VERSION ""

NS_ :

BS_:
BU_: aem_lambda
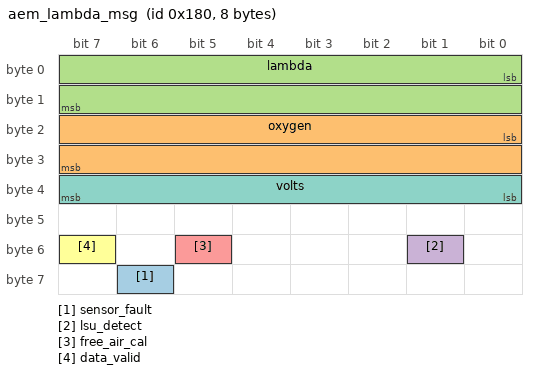
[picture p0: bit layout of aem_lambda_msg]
BO_ 384 aem_lambda_msg: 8 aem_lambda
   SG_ sensor_fault : 62|1@0+ (1,0) [0|1] "" Vector__XXX
   SG_ oxygen : 16|16@1- (1,0) [0|1] "" Vector__XXX
   SG_ lambda : 0|16@1+ (1,0) [0|1] "" Vector__XXX
   SG_ lsu_detect : 49|1@0+ (1,0) [0|1] "" Vector__XXX
   SG_ free_air_cal : 53|1@0+ (1,0) [0|1] "" Vector__XXX
   SG_ data_valid : 55|1@0+ (1,0) [0|1] "" Vector__XXX
   SG_ volts : 39|8@0+ (1,0) [0|1] "" Vector__XXX

BA_DEF_ BO_ "GenMsgBackgroundColor" STRING ;
BA_DEF_ BO_ "GenMsgForegroundColor" STRING ;
BA_DEF_ BO_ "filterlabeling" INT 0 0;
BA_DEF_DEF_ "GenMsgBackgroundColor" "#242424";
BA_DEF_DEF_ "GenMsgForegroundColor" "#f0f0f0";
BA_DEF_DEF_ "filterlabeling" 1;
